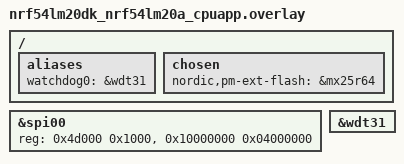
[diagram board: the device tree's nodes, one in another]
/*
 * Copyright (c) 2025 Nordic Semiconductor ASA
 *
 * SPDX-License-Identifier: LicenseRef-Nordic-5-Clause
 */

#include <samples/matter/nrf54lm20_cpuapp_partitions.dtsi>

/ {
	aliases {
		/* Use watchdog wdt31 as the application watchdog */
		watchdog0 = &wdt31;
	};

	chosen {
		nordic,pm-ext-flash = &mx25r64;
	};
};

/*
 * Workaround for nrf700x sysbuild helper expecting a node label `qspi`
 * with a `qspi_mm` reg-name on this board.
 */
qspi: &spi00 {
	reg = <0x4d000 0x1000>, <0x10000000 0x04000000>;
	reg-names = "qspi", "qspi_mm";
};

&wdt31 {
	status = "okay";
};
